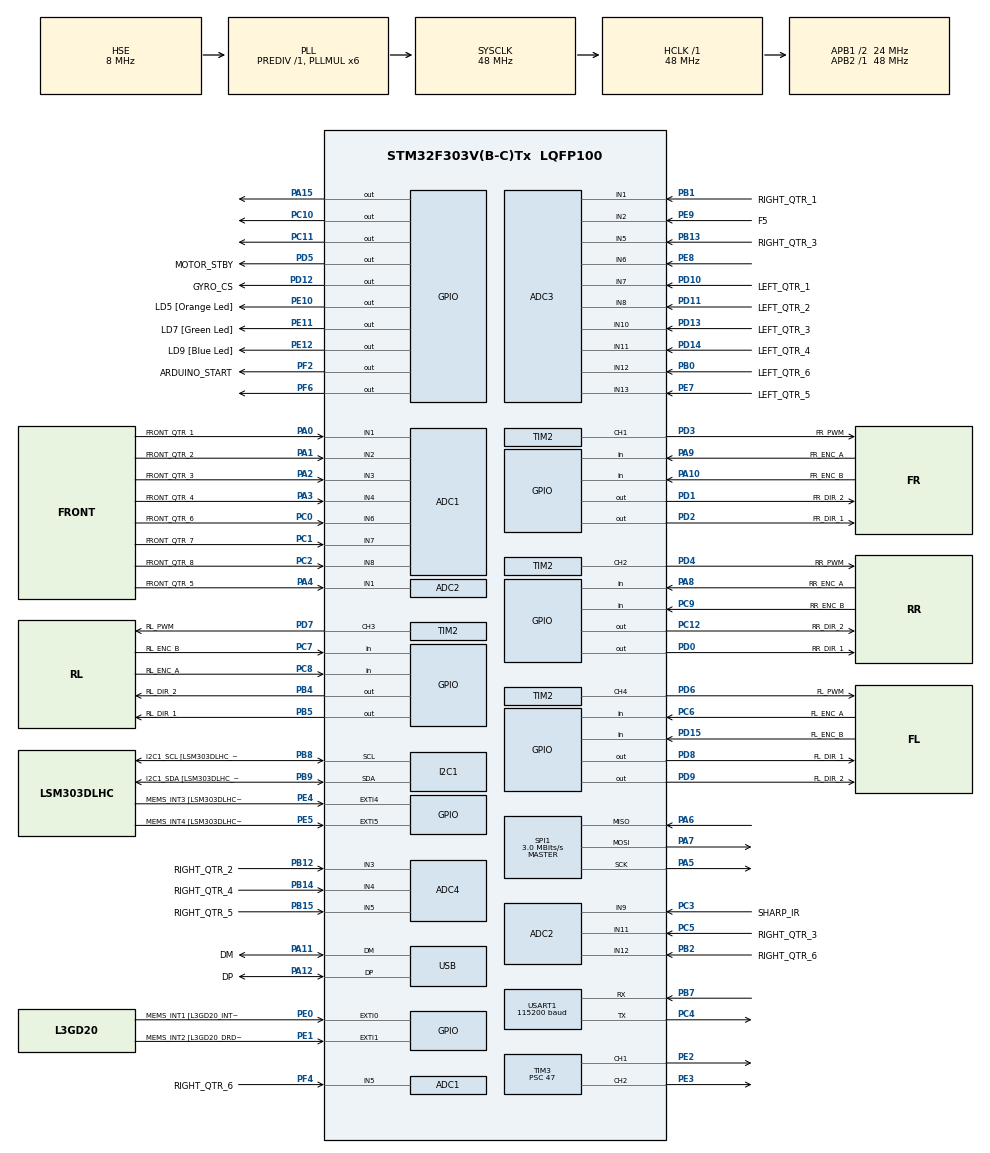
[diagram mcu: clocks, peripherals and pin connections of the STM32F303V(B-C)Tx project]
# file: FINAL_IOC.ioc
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ADC1.Channel-0\#ChannelRegularConversion=ADC_CHANNEL_6
ADC1.NbrOfConversionFlag=1
ADC1.Offset-0\#ChannelRegularConversion=0
ADC1.OffsetNumber-0\#ChannelRegularConversion=ADC_OFFSET_NONE
ADC1.Rank-0\#ChannelRegularConversion=1
ADC1.SamplingTime-0\#ChannelRegularConversion=ADC_SAMPLETIME_1CYCLE_5
ADC1.master=1
ADC2.Channel-0\#ChannelRegularConversion=ADC_CHANNEL_1
ADC2.NbrOfConversionFlag=1
ADC2.Offset-0\#ChannelRegularConversion=0
ADC2.OffsetNumber-0\#ChannelRegularConversion=ADC_OFFSET_NONE
ADC2.Rank-0\#ChannelRegularConversion=1
ADC2.SamplingTime-0\#ChannelRegularConversion=ADC_SAMPLETIME_1CYCLE_5
ADC3.Channel-0\#ChannelRegularConversion=ADC_CHANNEL_1
ADC3.NbrOfConversionFlag=1
ADC3.Offset-0\#ChannelRegularConversion=0
ADC3.OffsetNumber-0\#ChannelRegularConversion=ADC_OFFSET_NONE
ADC3.Rank-0\#ChannelRegularConversion=1
ADC3.SamplingTime-0\#ChannelRegularConversion=ADC_SAMPLETIME_1CYCLE_5
ADC3.master=1
ADC4.Channel-0\#ChannelRegularConversion=ADC_CHANNEL_3
ADC4.NbrOfConversionFlag=1
ADC4.Offset-0\#ChannelRegularConversion=0
ADC4.OffsetNumber-0\#ChannelRegularConversion=ADC_OFFSET_NONE
ADC4.Rank-0\#ChannelRegularConversion=1
ADC4.SamplingTime-0\#ChannelRegularConversion=ADC_SAMPLETIME_1CYCLE_5
Dma.ADC3.0.Direction=DMA_PERIPH_TO_MEMORY
Dma.ADC3.0.Instance=DMA2_Channel5
Dma.ADC3.0.MemDataAlignment=DMA_MDATAALIGN_HALFWORD
Dma.ADC3.0.MemInc=DMA_MINC_ENABLE
Dma.ADC3.0.Mode=DMA_CIRCULAR
Dma.ADC3.0.PeriphDataAlignment=DMA_PDATAALIGN_HALFWORD
Dma.ADC3.0.PeriphInc=DMA_PINC_DISABLE
Dma.ADC3.0.Priority=DMA_PRIORITY_LOW
Dma.Request0=ADC3
I2C1.Timing=0x00201D2B
Mcu.Family=STM32F3
Mcu.Name=STM32F303V(B-C)Tx
Mcu.Package=LQFP100
NVIC.ADC3_IRQn=true\:0\:0\:false\:false\:true\:true\:true\:true
NVIC.ADC4_IRQn=true\:0\:0\:false\:false\:true\:true\:true\:true
NVIC.DMA2_Channel5_IRQn=true\:0\:0\:false\:false\:true\:false\:true\:true
NVIC.PriorityGroup=NVIC_PRIORITYGROUP_0
NVIC.TIM6_DAC_IRQn=true\:0\:0\:false\:false\:true\:true\:true\:true
PA0.GPIO_Label=FRONT_QTR_1
PA0.Mode=IN1-Single-Ended
PA0.Signal=ADC1_IN1
PA1.GPIO_Label=FRONT_QTR_2
PA1.Mode=IN2-Single-Ended
PA1.Signal=ADC1_IN2
PA10.GPIO_Label=FR_ENC_B
PA10.GPIO_PuPd=GPIO_PULLUP
PA10.Signal=GPIO_Input
PA11.GPIO_Label=DM
PA11.Mode=Device
PA11.Signal=USB_DM
PA12.GPIO_Label=DP
PA12.Mode=Device
PA12.Signal=USB_DP
PA13.GPIO_Label=SWDIO
PA13.Mode=Serial_Wire
PA13.Signal=SYS_JTMS-SWDIO
PA14.Mode=Serial_Wire
PA14.Signal=SYS_JTCK-SWCLK
PA15.Signal=GPIO_Output
PA2.GPIO_Label=FRONT_QTR_3
PA2.Mode=IN3-Single-Ended
PA2.Signal=ADC1_IN3
PA3.GPIO_Label=FRONT_QTR_4
PA3.Mode=IN4-Single-Ended
PA3.Signal=ADC1_IN4
PA4.GPIO_Label=FRONT_QTR_5
PA4.Mode=IN1-Single-Ended
PA4.Signal=ADC2_IN1
PA5.Mode=Full_Duplex_Master
PA5.Signal=SPI1_SCK
PA6.Mode=Full_Duplex_Master
PA6.Signal=SPI1_MISO
PA7.Mode=Full_Duplex_Master
PA7.Signal=SPI1_MOSI
PA8.GPIO_Label=RR_ENC_A
PA8.GPIO_PuPd=GPIO_PULLUP
PA8.Signal=GPIO_Input
PA9.GPIO_Label=FR_ENC_A
PA9.GPIO_PuPd=GPIO_PULLUP
PA9.Signal=GPIO_Input
PB0.GPIO_Label=LEFT_QTR_6
PB0.Mode=IN12-Single-Ended
PB0.Signal=ADC3_IN12
PB1.GPIO_Label=RIGHT_QTR_1
PB1.Mode=IN1-Single-Ended
PB1.Signal=ADC3_IN1
PB12.GPIO_Label=RIGHT_QTR_2
PB12.Mode=IN3-Single-Ended
PB12.Signal=ADC4_IN3
PB13.GPIO_Label=RIGHT_QTR_3
PB13.Mode=IN5-Single-Ended
PB13.Signal=ADC3_IN5
PB14.GPIO_Label=RIGHT_QTR_4
PB14.Mode=IN4-Single-Ended
PB14.Signal=ADC4_IN4
PB15.GPIO_Label=RIGHT_QTR_5
PB15.Mode=IN5-Single-Ended
PB15.Signal=ADC4_IN5
PB2.GPIO_Label=RIGHT_QTR_6
PB2.Mode=IN12-Single-Ended
PB2.Signal=ADC2_IN12
PB3.GPIO_Label=SWO
PB3.Signal=SYS_JTDO-TRACESWO
PB4.GPIO_Label=RL_DIR_2
PB4.Signal=GPIO_Output
PB5.GPIO_Label=RL_DIR_1
PB5.Signal=GPIO_Output
PB7.Mode=Asynchronous
PB7.Signal=USART1_RX
PB8.GPIO_Label=I2C1_SCL [LSM303DLHC_SCL]
PB8.GPIO_Pu=GPIO_PULLUP
PB8.Mode=I2C
PB8.Signal=I2C1_SCL
PB9.GPIO_Label=I2C1_SDA [LSM303DLHC_SDA]
PB9.GPIO_Pu=GPIO_PULLUP
PB9.Mode=I2C
PB9.Signal=I2C1_SDA
PC0.GPIO_Label=FRONT_QTR_6
PC0.Signal=ADCx_IN6
PC1.GPIO_Label=FRONT_QTR_7
PC1.Signal=ADCx_IN7
PC10.Signal=GPIO_Output
PC11.Signal=GPIO_Output
PC12.GPIO_Label=RR_DIR_2
PC12.Signal=GPIO_Output
PC14-OSC32_IN.GPIO_Label=OSC32_IN
PC14-OSC32_IN.Signal=RCC_OSC32_IN
PC15-OSC32_OUT.GPIO_Label=OSC32_OUT
PC15-OSC32_OUT.Signal=RCC_OSC32_OUT
PC2.GPIO_Label=FRONT_QTR_8
PC2.Signal=ADCx_IN8
PC3.GPIO_Label=SHARP_IR
PC3.Signal=ADCx_IN9
PC4.Mode=Asynchronous
PC4.Signal=USART1_TX
PC5.GPIO_Label=RIGHT_QTR_3
PC5.Mode=IN11-Single-Ended
PC5.Signal=ADC2_IN11
PC6.GPIO_Label=FL_ENC_A
PC6.GPIO_PuPd=GPIO_PULLUP
PC6.Signal=GPIO_Input
PC7.GPIO_Label=RL_ENC_B
PC7.GPIO_PuPd=GPIO_PULLUP
PC7.Signal=GPIO_Input
PC8.GPIO_Label=RL_ENC_A
PC8.GPIO_PuPd=GPIO_PULLUP
PC8.Signal=GPIO_Input
PC9.GPIO_Label=RR_ENC_B
PC9.GPIO_PuPd=GPIO_PULLUP
PC9.Signal=GPIO_Input
PD0.GPIO_Label=RR_DIR_1
PD0.Signal=GPIO_Output
PD1.GPIO_Label=FR_DIR_2
PD1.Signal=GPIO_Output
PD10.GPIO_Label=LEFT_QTR_1
PD10.Signal=ADCx_IN7P
PD11.GPIO_Label=LEFT_QTR_2
PD11.Signal=ADCx_IN8P
PD12.GPIO_Label=GYRO_CS
PD12.PinState=GPIO_PIN_SET
PD12.Signal=GPIO_Output
PD13.GPIO_Label=LEFT_QTR_3
PD13.Signal=ADCx_IN10P
PD14.GPIO_Label=LEFT_QTR_4
PD14.Signal=ADCx_IN11
PD15.GPIO_Label=FL_ENC_B
PD15.GPIO_PuPd=GPIO_PULLUP
PD15.Signal=GPIO_Input
PD2.GPIO_Label=FR_DIR_1
PD2.Signal=GPIO_Output
PD3.GPIO_Label=FR_PWM
PD3.Signal=S_TIM2_CH1_ETR
PD4.GPIO_Label=RR_PWM
PD4.Signal=S_TIM2_CH2
PD5.GPIO_Label=MOTOR_STBY
PD5.Signal=GPIO_Output
PD6.GPIO_Label=FL_PWM
PD6.Signal=S_TIM2_CH4
PD7.GPIO_Label=RL_PWM
PD7.Signal=S_TIM2_CH3
PD8.GPIO_Label=FL_DIR_1
PD8.Signal=GPIO_Output
PD9.GPIO_Label=FL_DIR_2
PD9.Signal=GPIO_Output
PE0.GPIO_Label=MEMS_INT1 [L3GD20_INT1]
PE0.GPIO_ModeDefaultEXTI=GPIO_MODE_EVT_RISING
PE0.Signal=GPXTI0
PE1.GPIO_Label=MEMS_INT2 [L3GD20_DRDY/INT2]
PE1.GPIO_ModeDefaultEXTI=GPIO_MODE_EVT_RISING
PE1.Signal=GPXTI1
PE10.GPIO_Label=LD5 [Orange Led]
PE10.Signal=GPIO_Output
PE11.GPIO_Label=LD7 [Green Led]
PE11.Signal=GPIO_Output
PE12.GPIO_Label=LD9 [Blue Led]
PE12.Signal=GPIO_Output
PE2.Signal=S_TIM3_CH1
PE3.Signal=S_TIM3_CH2
PE4.GPIO_Label=MEMS_INT3 [LSM303DLHC_INT1]
PE4.GPIO_ModeDefaultEXTI=GPIO_MODE_EVT_RISING
PE4.Signal=GPXTI4
PE5.GPIO_Label=MEMS_INT4 [LSM303DLHC_INT2]
PE5.GPIO_ModeDefaultEXTI=GPIO_MODE_EVT_RISING
PE5.Signal=GPXTI5
PE7.GPIO_Label=LEFT_QTR_5
PE7.Mode=IN13-Single-Ended
PE7.Signal=ADC3_IN13
PE8.Signal=ADCx_IN6P
PE9.GPIO_Label=F5
PE9.Mode=IN2-Single-Ended
PE9.Signal=ADC3_IN2
PF0-OSC_IN.GPIO_Label=OSC_IN
PF0-OSC_IN.Mode=HSE-External-Clock-Source
PF0-OSC_IN.Signal=RCC_OSC_IN
PF1-OSC_OUT.GPIO_Label=OSC_OUT
PF1-OSC_OUT.Signal=RCC_OSC_OUT
PF2.GPIO_Label=ARDUINO_START
PF2.Signal=GPIO_Output
PF4.GPIO_Label=RIGHT_QTR_6
PF4.Mode=IN5-Single-Ended
PF4.Signal=ADC1_IN5
PF6.Signal=GPIO_Output
ProjectManager.HeapSize=0x200
ProjectManager.StackSize=0x400
ProjectManager.TargetToolchain=CMake
RCC.AHBFreq_Value=48000000
RCC.APB1CLKDivider=RCC_HCLK_DIV2
RCC.APB1Freq_Value=24000000
RCC.APB1TimFreq_Value=48000000
RCC.APB2Freq_Value=48000000
RCC.APB2TimFreq_Value=48000000
RCC.CortexFreq_Value=48000000
RCC.HCLKFreq_Value=48000000
RCC.HSE_VALUE=8000000
RCC.HSI_VALUE=8000000
RCC.LSE_VALUE=32768
RCC.PLLMUL=RCC_PLL_MUL6
RCC.SYSCLKFreq_VALUE=48000000
RCC.SYSCLKSourceVirtual=RCC_SYSCLKSOURCE_PLLCLK
RCC.USBFreq_Value=48000000
SH.ADCx_IN10P.0=ADC3_IN10,IN10-Single-Ended
SH.ADCx_IN11.0=ADC3_IN11,IN11-Single-Ended
SH.ADCx_IN6.0=ADC1_IN6,IN6-Single-Ended
SH.ADCx_IN6P.0=ADC3_IN6,IN6-Single-Ended
SH.ADCx_IN7.0=ADC1_IN7,IN7-Single-Ended
SH.ADCx_IN7P.0=ADC3_IN7,IN7-Single-Ended
SH.ADCx_IN8.0=ADC1_IN8,IN8-Single-Ended
SH.ADCx_IN8P.0=ADC3_IN8,IN8-Single-Ended
SH.ADCx_IN9.0=ADC2_IN9,IN9-Single-Ended
SH.S_TIM2_CH1_ETR.0=TIM2_CH1,PWM Generation1 CH1
SH.S_TIM2_CH2.0=TIM2_CH2,PWM Generation2 CH2
SH.S_TIM2_CH3.0=TIM2_CH3,PWM Generation3 CH3
SH.S_TIM2_CH4.0=TIM2_CH4,PWM Generation4 CH4
SH.S_TIM3_CH1.0=TIM3_CH1,PWM Generation1 CH1
SH.S_TIM3_CH2.0=TIM3_CH2,PWM Generation2 CH2
SPI1.BaudRatePrescaler=SPI_BAUDRATEPRESCALER_16
SPI1.CLKPhase=SPI_PHASE_2EDGE
SPI1.CLKPolarity=SPI_POLARITY_HIGH
SPI1.CalculateBaudRate=3.0 MBits/s
SPI1.DataSize=SPI_DATASIZE_8BIT
SPI1.Direction=SPI_DIRECTION_2LINES
SPI1.Mode=SPI_MODE_MASTER
SPI1.VirtualType=VM_MASTER
TIM2.Channel-PWM\ Generation1\ CH1=TIM_CHANNEL_1
TIM2.Channel-PWM\ Generation2\ CH2=TIM_CHANNEL_2
TIM2.Channel-PWM\ Generation3\ CH3=TIM_CHANNEL_3
TIM2.Channel-PWM\ Generation4\ CH4=TIM_CHANNEL_4
TIM2.Period=4799
TIM3.Channel-PWM\ Generation1\ CH1=TIM_CHANNEL_1
TIM3.Channel-PWM\ Generation2\ CH2=TIM_CHANNEL_2
TIM3.Period=19999
TIM3.Prescaler=47
TIM6.Period=2399 
USART1.BaudRate=115200
USART1.Mode=MODE_TX
USART1.VirtualMode-Asynchronous=VM_ASYNC
VP_TIM1_VS_ClockSourceINT.Mode=Internal
VP_TIM2_VS_ClockSourceINT.Mode=Internal
VP_TIM3_VS_ClockSourceINT.Mode=Internal
VP_TIM6_VS_ClockSourceINT.Mode=Enable_Timer
board=STM32F3DISCOVERY

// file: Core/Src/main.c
/* USER CODE BEGIN Header */
/**
  ******************************************************************************
  * @file           : main.c
  * @brief          : Main program body
  ******************************************************************************
  * @attention
  *
  * Copyright (c) 2026 STMicroelectronics.
  * All rights reserved.
  *
  * This software is licensed under terms that can be found in the LICENSE file
  * in the root directory of this software component.
  * If no LICENSE file comes with this software, it is provided AS-IS.
  *
  ******************************************************************************
  */
/* USER CODE END Header */
#include "main.h"

/* USER CODE BEGIN Includes */
#include "robot_core.h"
#include <stdio.h>
#include <stdbool.h>
#include "tcs34725.h"
/* USER CODE END Includes */

ADC_HandleTypeDef hadc1;
ADC_HandleTypeDef hadc2;
ADC_HandleTypeDef hadc3;
ADC_HandleTypeDef hadc4;
DMA_HandleTypeDef hdma_adc3;

I2C_HandleTypeDef hi2c1;

SPI_HandleTypeDef hspi1;

TIM_HandleTypeDef htim1;
TIM_HandleTypeDef htim2;
TIM_HandleTypeDef htim3;
TIM_HandleTypeDef htim6;

UART_HandleTypeDef huart1;

PCD_HandleTypeDef hpcd_USB_FS;

void SystemClock_Config(void);
static void MX_GPIO_Init(void);
static void MX_DMA_Init(void);
static void MX_TIM2_Init(void);
static void MX_USB_PCD_Init(void);
static void MX_TIM1_Init(void);
static void MX_TIM3_Init(void);
static void MX_USART1_UART_Init(void);
static void MX_TIM6_Init(void);
static void MX_ADC1_Init(void);
static void MX_ADC2_Init(void);
static void MX_ADC3_Init(void);
static void MX_ADC4_Init(void);
static void MX_SPI1_Init(void);
static void MX_I2C1_Init(void);

/* USER CODE BEGIN 0 */
int _write(int file, char *ptr, int len) {
    HAL_UART_Transmit(&huart1, (uint8_t*)ptr, len, HAL_MAX_DELAY);
    return len;
}

// // Trapezoidal Deceleration: Smoothly ramps down motor speeds to 0 to protect power supplies
// void Chassis_SmoothStop(Mecanum_Chassis_t *ch, int32_t start_vx, int32_t start_vy, int32_t start_omega, uint32_t duration_ms) {
//     uint32_t steps = 6;
//     uint32_t step_delay = duration_ms / steps;
//     for (int i = (int)steps; i >= 0; i--) {
//         int32_t vx = (start_vx * i) / (int32_t)steps;
//         int32_t vy = (start_vy * i) / (int32_t)steps;
//         int32_t omega = (start_omega * i) / (int32_t)steps;
//         Chassis_Drive(ch, vx, vy, omega);
//         HAL_Delay(step_delay);
//     }
//     Chassis_Drive(ch, 0, 0, 0);
// }
/* USER CODE END 0 */

int main(void)
{

  /* MCU Configuration--------------------------------------------------------*/

  /* Reset of all peripherals, Initializes the Flash interface and the Systick. */
  HAL_Init();

  /* Configure the system clock */
  SystemClock_Config();

  /* USER CODE BEGIN SysInit */
  MX_USART1_UART_Init();
  printf("\r\n==================================\r\n");
  printf("  NERC ROBOT EARLY BOOT DIAGNOSTIC\r\n");
  printf("==================================\r\n");
  /* USER CODE END SysInit */

  /* Initialize all configured peripherals */
  MX_GPIO_Init();
  MX_DMA_Init();
  MX_TIM2_Init();
  MX_USB_PCD_Init();
  MX_TIM1_Init();
  MX_TIM3_Init();
  MX_USART1_UART_Init();
  MX_TIM6_Init();
  MX_ADC1_Init();
  MX_ADC2_Init();
  MX_ADC3_Init();
  MX_ADC4_Init();
  MX_SPI1_Init();
  MX_I2C1_Init();
  /* USER CODE BEGIN 2 */
  HAL_ADCEx_Calibration_Start(&hadc1, ADC_SINGLE_ENDED);
  HAL_ADCEx_Calibration_Start(&hadc2, ADC_SINGLE_ENDED);
  HAL_ADCEx_Calibration_Start(&hadc3, ADC_SINGLE_ENDED);
  HAL_ADCEx_Calibration_Start(&hadc4, ADC_SINGLE_ENDED);

  if (TCS34725_Init(&hi2c1) != HAL_OK) {
      /* Initialization Error handling could go here */
      printf("TCS34725 Init Failed!\r\n");
  }

  Robot_Init();
  /* USER CODE END 2 */

  /* Infinite loop */
  while (1)
  {

    /* USER CODE BEGIN 3 */
    Robot_RunLoop();
  }
  /* USER CODE END 3 */
}

void SystemClock_Config(void)
{
  RCC_OscInitTypeDef RCC_OscInitStruct = {0};
  RCC_ClkInitTypeDef RCC_ClkInitStruct = {0};
  RCC_PeriphCLKInitTypeDef PeriphClkInit = {0};

  /** Initializes the RCC Oscillators according to the specified parameters
  * in the RCC_OscInitTypeDef structure.
  */
  RCC_OscInitStruct.OscillatorType = RCC_OSCILLATORTYPE_HSI|RCC_OSCILLATORTYPE_HSE;
  RCC_OscInitStruct.HSEState = RCC_HSE_BYPASS;
  RCC_OscInitStruct.HSEPredivValue = RCC_HSE_PREDIV_DIV1;
  RCC_OscInitStruct.HSIState = RCC_HSI_ON;
  RCC_OscInitStruct.HSICalibrationValue = RCC_HSICALIBRATION_DEFAULT;
  RCC_OscInitStruct.PLL.PLLState = RCC_PLL_ON;
  RCC_OscInitStruct.PLL.PLLSource = RCC_PLLSOURCE_HSE;
  RCC_OscInitStruct.PLL.PLLMUL = RCC_PLL_MUL6;
  if (HAL_RCC_OscConfig(&RCC_OscInitStruct) != HAL_OK)
  {
    Error_Handler();
  }

  /** Initializes the CPU, AHB and APB buses clocks
  */
  RCC_ClkInitStruct.ClockType = RCC_CLOCKTYPE_HCLK|RCC_CLOCKTYPE_SYSCLK
                              |RCC_CLOCKTYPE_PCLK1|RCC_CLOCKTYPE_PCLK2;
  RCC_ClkInitStruct.SYSCLKSource = RCC_SYSCLKSOURCE_PLLCLK;
  RCC_ClkInitStruct.AHBCLKDivider = RCC_SYSCLK_DIV1;
  RCC_ClkInitStruct.APB1CLKDivider = RCC_HCLK_DIV2;
  RCC_ClkInitStruct.APB2CLKDivider = RCC_HCLK_DIV1;

  if (HAL_RCC_ClockConfig(&RCC_ClkInitStruct, FLASH_LATENCY_1) != HAL_OK)
  {
    Error_Handler();
  }
  PeriphClkInit.PeriphClockSelection = RCC_PERIPHCLK_USB|RCC_PERIPHCLK_USART1
                              |RCC_PERIPHCLK_I2C1|RCC_PERIPHCLK_TIM1
                              |RCC_PERIPHCLK_ADC12|RCC_PERIPHCLK_ADC34;
  PeriphClkInit.Usart1ClockSelection = RCC_USART1CLKSOURCE_PCLK2;
  PeriphClkInit.Adc12ClockSelection = RCC_ADC12PLLCLK_DIV1;
  PeriphClkInit.Adc34ClockSelection = RCC_ADC34PLLCLK_DIV1;
  PeriphClkInit.I2c1ClockSelection = RCC_I2C1CLKSOURCE_HSI;
  PeriphClkInit.USBClockSelection = RCC_USBCLKSOURCE_PLL;
  PeriphClkInit.Tim1ClockSelection = RCC_TIM1CLK_HCLK;
  if (HAL_RCCEx_PeriphCLKConfig(&PeriphClkInit) != HAL_OK)
  {
    Error_Handler();
  }
}

static void MX_ADC1_Init(void)
{

  ADC_MultiModeTypeDef multimode = {0};
  ADC_ChannelConfTypeDef sConfig = {0};

  /** Common config
  */
  hadc1.Instance = ADC1;
  hadc1.Init.ClockPrescaler = ADC_CLOCK_ASYNC_DIV1;
  hadc1.Init.Resolution = ADC_RESOLUTION_12B;
  hadc1.Init.ScanConvMode = ADC_SCAN_DISABLE;
  hadc1.Init.ContinuousConvMode = DISABLE;
  hadc1.Init.DiscontinuousConvMode = DISABLE;
  hadc1.Init.ExternalTrigConvEdge = ADC_EXTERNALTRIGCONVEDGE_NONE;
  hadc1.Init.ExternalTrigConv = ADC_SOFTWARE_START;
  hadc1.Init.DataAlign = ADC_DATAALIGN_RIGHT;
  hadc1.Init.NbrOfConversion = 1;
  hadc1.Init.DMAContinuousRequests = DISABLE;
  hadc1.Init.EOCSelection = ADC_EOC_SINGLE_CONV;
  hadc1.Init.LowPowerAutoWait = DISABLE;
  hadc1.Init.Overrun = ADC_OVR_DATA_OVERWRITTEN;
  if (HAL_ADC_Init(&hadc1) != HAL_OK)
  {
    Error_Handler();
  }

  /** Configure the ADC multi-mode
  */
  multimode.Mode = ADC_MODE_INDEPENDENT;
  if (HAL_ADCEx_MultiModeConfigChannel(&hadc1, &multimode) != HAL_OK)
  {
    Error_Handler();
  }

  /** Configure Regular Channel
  */
  sConfig.Channel = ADC_CHANNEL_6;
  sConfig.Rank = ADC_REGULAR_RANK_1;
  sConfig.SingleDiff = ADC_SINGLE_ENDED;
  sConfig.SamplingTime = ADC_SAMPLETIME_1CYCLE_5;
  sConfig.OffsetNumber = ADC_OFFSET_NONE;
  sConfig.Offset = 0;
  if (HAL_ADC_ConfigChannel(&hadc1, &sConfig) != HAL_OK)
  {
    Error_Handler();
  }

}

static void MX_ADC2_Init(void)
{

  ADC_ChannelConfTypeDef sConfig = {0};

  /** Common config
  */
  hadc2.Instance = ADC2;
  hadc2.Init.ClockPrescaler = ADC_CLOCK_ASYNC_DIV1;
  hadc2.Init.Resolution = ADC_RESOLUTION_12B;
  hadc2.Init.ScanConvMode = ADC_SCAN_DISABLE;
  hadc2.Init.ContinuousConvMode = DISABLE;
  hadc2.Init.DiscontinuousConvMode = DISABLE;
  hadc2.Init.ExternalTrigConvEdge = ADC_EXTERNALTRIGCONVEDGE_NONE;
  hadc2.Init.ExternalTrigConv = ADC_SOFTWARE_START;
  hadc2.Init.DataAlign = ADC_DATAALIGN_RIGHT;
  hadc2.Init.NbrOfConversion = 1;
  hadc2.Init.DMAContinuousRequests = DISABLE;
  hadc2.Init.EOCSelection = ADC_EOC_SINGLE_CONV;
  hadc2.Init.LowPowerAutoWait = DISABLE;
  hadc2.Init.Overrun = ADC_OVR_DATA_OVERWRITTEN;
  if (HAL_ADC_Init(&hadc2) != HAL_OK)
  {
    Error_Handler();
  }

  /** Configure Regular Channel
  */
  sConfig.Channel = ADC_CHANNEL_1;
  sConfig.Rank = ADC_REGULAR_RANK_1;
  sConfig.SingleDiff = ADC_SINGLE_ENDED;
  sConfig.SamplingTime = ADC_SAMPLETIME_1CYCLE_5;
  sConfig.OffsetNumber = ADC_OFFSET_NONE;
  sConfig.Offset = 0;
  if (HAL_ADC_ConfigChannel(&hadc2, &sConfig) != HAL_OK)
  {
    Error_Handler();
  }

}

static void MX_ADC3_Init(void)
{

  ADC_MultiModeTypeDef multimode = {0};
  ADC_ChannelConfTypeDef sConfig = {0};

  /** Common config
  */
  hadc3.Instance = ADC3;
  hadc3.Init.ClockPrescaler = ADC_CLOCK_ASYNC_DIV1;
  hadc3.Init.Resolution = ADC_RESOLUTION_12B;
  hadc3.Init.ScanConvMode = ADC_SCAN_DISABLE;
  hadc3.Init.ContinuousConvMode = DISABLE;
  hadc3.Init.DiscontinuousConvMode = DISABLE;
  hadc3.Init.ExternalTrigConvEdge = ADC_EXTERNALTRIGCONVEDGE_NONE;
  hadc3.Init.ExternalTrigConv = ADC_SOFTWARE_START;
  hadc3.Init.DataAlign = ADC_DATAALIGN_RIGHT;
  hadc3.Init.NbrOfConversion = 1;
  hadc3.Init.DMAContinuousRequests = DISABLE;
  hadc3.Init.EOCSelection = ADC_EOC_SINGLE_CONV;
  hadc3.Init.LowPowerAutoWait = DISABLE;
  hadc3.Init.Overrun = ADC_OVR_DATA_OVERWRITTEN;
  if (HAL_ADC_Init(&hadc3) != HAL_OK)
  {
    Error_Handler();
  }

  /** Configure the ADC multi-mode
  */
  multimode.Mode = ADC_MODE_INDEPENDENT;
  if (HAL_ADCEx_MultiModeConfigChannel(&hadc3, &multimode) != HAL_OK)
  {
    Error_Handler();
  }

  /** Configure Regular Channel
  */
  sConfig.Channel = ADC_CHANNEL_1;
  sConfig.Rank = ADC_REGULAR_RANK_1;
  sConfig.SingleDiff = ADC_SINGLE_ENDED;
  sConfig.SamplingTime = ADC_SAMPLETIME_1CYCLE_5;
  sConfig.OffsetNumber = ADC_OFFSET_NONE;
  sConfig.Offset = 0;
  if (HAL_ADC_ConfigChannel(&hadc3, &sConfig) != HAL_OK)
  {
    Error_Handler();
  }

}

static void MX_ADC4_Init(void)
{

  ADC_ChannelConfTypeDef sConfig = {0};

  /** Common config
  */
  hadc4.Instance = ADC4;
  hadc4.Init.ClockPrescaler = ADC_CLOCK_ASYNC_DIV1;
  hadc4.Init.Resolution = ADC_RESOLUTION_12B;
  hadc4.Init.ScanConvMode = ADC_SCAN_DISABLE;
  hadc4.Init.ContinuousConvMode = DISABLE;
  hadc4.Init.DiscontinuousConvMode = DISABLE;
  hadc4.Init.ExternalTrigConvEdge = ADC_EXTERNALTRIGCONVEDGE_NONE;
  hadc4.Init.ExternalTrigConv = ADC_SOFTWARE_START;
  hadc4.Init.DataAlign = ADC_DATAALIGN_RIGHT;
  hadc4.Init.NbrOfConversion = 1;
  hadc4.Init.DMAContinuousRequests = DISABLE;
  hadc4.Init.EOCSelection = ADC_EOC_SINGLE_CONV;
  hadc4.Init.LowPowerAutoWait = DISABLE;
  hadc4.Init.Overrun = ADC_OVR_DATA_OVERWRITTEN;
  if (HAL_ADC_Init(&hadc4) != HAL_OK)
  {
    Error_Handler();
  }

  /** Configure Regular Channel
  */
  sConfig.Channel = ADC_CHANNEL_3;
  sConfig.Rank = ADC_REGULAR_RANK_1;
  sConfig.SingleDiff = ADC_SINGLE_ENDED;
  sConfig.SamplingTime = ADC_SAMPLETIME_1CYCLE_5;
  sConfig.OffsetNumber = ADC_OFFSET_NONE;
  sConfig.Offset = 0;
  if (HAL_ADC_ConfigChannel(&hadc4, &sConfig) != HAL_OK)
  {
    Error_Handler();
  }

}

static void MX_I2C1_Init(void)
{

  hi2c1.Instance = I2C1;
  hi2c1.Init.Timing = 0x00201D2B;
  hi2c1.Init.OwnAddress1 = 0;
  hi2c1.Init.AddressingMode = I2C_ADDRESSINGMODE_7BIT;
  hi2c1.Init.DualAddressMode = I2C_DUALADDRESS_DISABLE;
  hi2c1.Init.OwnAddress2 = 0;
  hi2c1.Init.OwnAddress2Masks = I2C_OA2_NOMASK;
  hi2c1.Init.GeneralCallMode = I2C_GENERALCALL_DISABLE;
  hi2c1.Init.NoStretchMode = I2C_NOSTRETCH_DISABLE;
  if (HAL_I2C_Init(&hi2c1) != HAL_OK)
  {
    Error_Handler();
  }

  /** Configure Analogue filter
  */
  if (HAL_I2CEx_ConfigAnalogFilter(&hi2c1, I2C_ANALOGFILTER_ENABLE) != HAL_OK)
  {
    Error_Handler();
  }

  /** Configure Digital filter
  */
  if (HAL_I2CEx_ConfigDigitalFilter(&hi2c1, 0) != HAL_OK)
  {
    Error_Handler();
  }

}

static void MX_SPI1_Init(void)
{

  /* SPI1 parameter configuration*/
  hspi1.Instance = SPI1;
  hspi1.Init.Mode = SPI_MODE_MASTER;
  hspi1.Init.Direction = SPI_DIRECTION_2LINES;
  hspi1.Init.DataSize = SPI_DATASIZE_8BIT;
  hspi1.Init.CLKPolarity = SPI_POLARITY_HIGH;
  hspi1.Init.CLKPhase = SPI_PHASE_2EDGE;
  hspi1.Init.NSS = SPI_NSS_SOFT;
  hspi1.Init.BaudRatePrescaler = SPI_BAUDRATEPRESCALER_16;
  hspi1.Init.FirstBit = SPI_FIRSTBIT_MSB;
  hspi1.Init.TIMode = SPI_TIMODE_DISABLE;
  hspi1.Init.CRCCalculation = SPI_CRCCALCULATION_DISABLE;
  hspi1.Init.CRCPolynomial = 7;
  hspi1.Init.CRCLength = SPI_CRC_LENGTH_DATASIZE;
  hspi1.Init.NSSPMode = SPI_NSS_PULSE_DISABLE;
  if (HAL_SPI_Init(&hspi1) != HAL_OK)
  {
    Error_Handler();
  }

}

static void MX_TIM1_Init(void)
{

  TIM_ClockConfigTypeDef sClockSourceConfig = {0};
  TIM_MasterConfigTypeDef sMasterConfig = {0};

  htim1.Instance = TIM1;
  htim1.Init.Prescaler = 0;
  htim1.Init.CounterMode = TIM_COUNTERMODE_UP;
  htim1.Init.Period = 65535;
  htim1.Init.ClockDivision = TIM_CLOCKDIVISION_DIV1;
  htim1.Init.RepetitionCounter = 0;
  htim1.Init.AutoReloadPreload = TIM_AUTORELOAD_PRELOAD_DISABLE;
  if (HAL_TIM_Base_Init(&htim1) != HAL_OK)
  {
    Error_Handler();
  }
  sClockSourceConfig.ClockSource = TIM_CLOCKSOURCE_INTERNAL;
  if (HAL_TIM_ConfigClockSource(&htim1, &sClockSourceConfig) != HAL_OK)
  {
    Error_Handler();
  }
  sMasterConfig.MasterOutputTrigger = TIM_TRGO_RESET;
  sMasterConfig.MasterOutputTrigger2 = TIM_TRGO2_RESET;
  sMasterConfig.MasterSlaveMode = TIM_MASTERSLAVEMODE_DISABLE;
  if (HAL_TIMEx_MasterConfigSynchronization(&htim1, &sMasterConfig) != HAL_OK)
  {
    Error_Handler();
  }

}

static void MX_TIM2_Init(void)
{

  TIM_ClockConfigTypeDef sClockSourceConfig = {0};
  TIM_MasterConfigTypeDef sMasterConfig = {0};
  TIM_OC_InitTypeDef sConfigOC = {0};

  htim2.Instance = TIM2;
  htim2.Init.Prescaler = 0;
  htim2.Init.CounterMode = TIM_COUNTERMODE_UP;
  htim2.Init.Period = 4799;
  htim2.Init.ClockDivision = TIM_CLOCKDIVISION_DIV1;
  htim2.Init.AutoReloadPreload = TIM_AUTORELOAD_PRELOAD_DISABLE;
  if (HAL_TIM_Base_Init(&htim2) != HAL_OK)
  {
    Error_Handler();
  }
  sClockSourceConfig.ClockSource = TIM_CLOCKSOURCE_INTERNAL;
  if (HAL_TIM_ConfigClockSource(&htim2, &sClockSourceConfig) != HAL_OK)
  {
    Error_Handler();
  }
  if (HAL_TIM_PWM_Init(&htim2) != HAL_OK)
  {
    Error_Handler();
  }
  sMasterConfig.MasterOutputTrigger = TIM_TRGO_RESET;
  sMasterConfig.MasterSlaveMode = TIM_MASTERSLAVEMODE_DISABLE;
  if (HAL_TIMEx_MasterConfigSynchronization(&htim2, &sMasterConfig) != HAL_OK)
  {
    Error_Handler();
  }
  sConfigOC.OCMode = TIM_OCMODE_PWM1;
  sConfigOC.Pulse = 0;
  sConfigOC.OCPolarity = TIM_OCPOLARITY_HIGH;
  sConfigOC.OCFastMode = TIM_OCFAST_DISABLE;
  if (HAL_TIM_PWM_ConfigChannel(&htim2, &sConfigOC, TIM_CHANNEL_1) != HAL_OK)
  {
    Error_Handler();
  }
  if (HAL_TIM_PWM_ConfigChannel(&htim2, &sConfigOC, TIM_CHANNEL_2) != HAL_OK)
  {
    Error_Handler();
  }
  if (HAL_TIM_PWM_ConfigChannel(&htim2, &sConfigOC, TIM_CHANNEL_3) != HAL_OK)
  {
    Error_Handler();
  }
  if (HAL_TIM_PWM_ConfigChannel(&htim2, &sConfigOC, TIM_CHANNEL_4) != HAL_OK)
  {
    Error_Handler();
  }
  HAL_TIM_MspPostInit(&htim2);

}

static void MX_TIM3_Init(void)
{

  TIM_ClockConfigTypeDef sClockSourceConfig = {0};
  TIM_MasterConfigTypeDef sMasterConfig = {0};
  TIM_OC_InitTypeDef sConfigOC = {0};

  htim3.Instance = TIM3;
  htim3.Init.Prescaler = 47;
  htim3.Init.CounterMode = TIM_COUNTERMODE_UP;
  htim3.Init.Period = 19999;
  htim3.Init.ClockDivision = TIM_CLOCKDIVISION_DIV1;
  htim3.Init.AutoReloadPreload = TIM_AUTORELOAD_PRELOAD_DISABLE;
  if (HAL_TIM_Base_Init(&htim3) != HAL_OK)
  {
    Error_Handler();
  }
  sClockSourceConfig.ClockSource = TIM_CLOCKSOURCE_INTERNAL;
  if (HAL_TIM_ConfigClockSource(&htim3, &sClockSourceConfig) != HAL_OK)
  {
    Error_Handler();
  }
  if (HAL_TIM_PWM_Init(&htim3) != HAL_OK)
  {
    Error_Handler();
  }
  sMasterConfig.MasterOutputTrigger = TIM_TRGO_RESET;
  sMasterConfig.MasterSlaveMode = TIM_MASTERSLAVEMODE_DISABLE;
  if (HAL_TIMEx_MasterConfigSynchronization(&htim3, &sMasterConfig) != HAL_OK)
  {
    Error_Handler();
  }
  sConfigOC.OCMode = TIM_OCMODE_PWM1;
  sConfigOC.Pulse = 0;
  sConfigOC.OCPolarity = TIM_OCPOLARITY_HIGH;
  sConfigOC.OCFastMode = TIM_OCFAST_DISABLE;
  if (HAL_TIM_PWM_ConfigChannel(&htim3, &sConfigOC, TIM_CHANNEL_1) != HAL_OK)
  {
    Error_Handler();
  }
  if (HAL_TIM_PWM_ConfigChannel(&htim3, &sConfigOC, TIM_CHANNEL_2) != HAL_OK)
  {
    Error_Handler();
  }
  HAL_TIM_MspPostInit(&htim3);

}

static void MX_TIM6_Init(void)
{

  TIM_MasterConfigTypeDef sMasterConfig = {0};

  htim6.Instance = TIM6;
  htim6.Init.Prescaler = 0;
  htim6.Init.CounterMode = TIM_COUNTERMODE_UP;
  htim6.Init.Period = 2399 ;
  htim6.Init.AutoReloadPreload = TIM_AUTORELOAD_PRELOAD_DISABLE;
  if (HAL_TIM_Base_Init(&htim6) != HAL_OK)
  {
    Error_Handler();
  }
  sMasterConfig.MasterOutputTrigger = TIM_TRGO_RESET;
  sMasterConfig.MasterSlaveMode = TIM_MASTERSLAVEMODE_DISABLE;
  if (HAL_TIMEx_MasterConfigSynchronization(&htim6, &sMasterConfig) != HAL_OK)
  {
    Error_Handler();
  }

}

static void MX_USART1_UART_Init(void)
{

  huart1.Instance = USART1;
  huart1.Init.BaudRate = 115200;
  huart1.Init.WordLength = UART_WORDLENGTH_8B;
  huart1.Init.StopBits = UART_STOPBITS_1;
  huart1.Init.Parity = UART_PARITY_NONE;
  huart1.Init.Mode = UART_MODE_TX;
  huart1.Init.HwFlowCtl = UART_HWCONTROL_NONE;
  huart1.Init.OverSampling = UART_OVERSAMPLING_16;
  huart1.Init.OneBitSampling = UART_ONE_BIT_SAMPLE_DISABLE;
  huart1.AdvancedInit.AdvFeatureInit = UART_ADVFEATURE_NO_INIT;
  if (HAL_UART_Init(&huart1) != HAL_OK)
  {
    Error_Handler();
  }

}

static void MX_USB_PCD_Init(void)
{

  hpcd_USB_FS.Instance = USB;
  hpcd_USB_FS.Init.dev_endpoints = 8;
  hpcd_USB_FS.Init.speed = PCD_SPEED_FULL;
  hpcd_USB_FS.Init.phy_itface = PCD_PHY_EMBEDDED;
  hpcd_USB_FS.Init.low_power_enable = DISABLE;
  hpcd_USB_FS.Init.battery_charging_enable = DISABLE;
  if (HAL_PCD_Init(&hpcd_USB_FS) != HAL_OK)
  {
    Error_Handler();
  }

}

static void MX_DMA_Init(void)
{

  /* DMA controller clock enable */
  __HAL_RCC_DMA2_CLK_ENABLE();

  /* DMA interrupt init */
  /* DMA2_Channel5_IRQn interrupt configuration */
  HAL_NVIC_SetPriority(DMA2_Channel5_IRQn, 0, 0);
  HAL_NVIC_EnableIRQ(DMA2_Channel5_IRQn);

}

static void MX_GPIO_Init(void)
{
  GPIO_InitTypeDef GPIO_InitStruct = {0};

  /* GPIO Ports Clock Enable */
  __HAL_RCC_GPIOE_CLK_ENABLE();
  __HAL_RCC_GPIOC_CLK_ENABLE();
  __HAL_RCC_GPIOF_CLK_ENABLE();
  __HAL_RCC_GPIOA_CLK_ENABLE();
  __HAL_RCC_GPIOB_CLK_ENABLE();
  __HAL_RCC_GPIOD_CLK_ENABLE();

  /*Configure GPIO pin Output Level */
  HAL_GPIO_WritePin(GPIOF, ARDUINO_START_Pin|GPIO_PIN_6, GPIO_PIN_RESET);

  /*Configure GPIO pin Output Level */
  HAL_GPIO_WritePin(GPIOE, LD5_Pin|LD7_Pin|LD9_Pin, GPIO_PIN_RESET);

  /*Configure GPIO pin Output Level */
  HAL_GPIO_WritePin(GPIOD, FL_DIR_1_Pin|FL_DIR_2_Pin|RR_DIR_1_Pin|FR_DIR_2_Pin
                          |FR_DIR_1_Pin|MOTOR_STBY_Pin, GPIO_PIN_RESET);

  /*Configure GPIO pin Output Level */
  HAL_GPIO_WritePin(GYRO_CS_GPIO_Port, GYRO_CS_Pin, GPIO_PIN_SET);

  /*Configure GPIO pin Output Level */
  HAL_GPIO_WritePin(GPIOA, GPIO_PIN_15, GPIO_PIN_RESET);

  /*Configure GPIO pin Output Level */
  HAL_GPIO_WritePin(GPIOC, GPIO_PIN_10|GPIO_PIN_11|RR_DIR_2_Pin, GPIO_PIN_RESET);

  /*Configure GPIO pin Output Level */
  HAL_GPIO_WritePin(GPIOB, RL_DIR_2_Pin|RL_DIR_1_Pin, GPIO_PIN_RESET);

  /*Configure GPIO pins : MEMS_INT3_Pin MEMS_INT4_Pin MEMS_INT1_Pin MEMS_INT2_Pin */
  GPIO_InitStruct.Pin = MEMS_INT3_Pin|MEMS_INT4_Pin|MEMS_INT1_Pin|MEMS_INT2_Pin;
  GPIO_InitStruct.Mode = GPIO_MODE_EVT_RISING;
  GPIO_InitStruct.Pull = GPIO_NOPULL;
  HAL_GPIO_Init(GPIOE, &GPIO_InitStruct);

  /*Configure GPIO pins : ARDUINO_START_Pin PF6 */
  GPIO_InitStruct.Pin = ARDUINO_START_Pin|GPIO_PIN_6;
  GPIO_InitStruct.Mode = GPIO_MODE_OUTPUT_PP;
  GPIO_InitStruct.Pull = GPIO_NOPULL;
  GPIO_InitStruct.Speed = GPIO_SPEED_FREQ_LOW;
  HAL_GPIO_Init(GPIOF, &GPIO_InitStruct);

  /*Configure GPIO pins : LD5_Pin LD7_Pin LD9_Pin */
  GPIO_InitStruct.Pin = LD5_Pin|LD7_Pin|LD9_Pin;
  GPIO_InitStruct.Mode = GPIO_MODE_OUTPUT_PP;
  GPIO_InitStruct.Pull = GPIO_NOPULL;
  GPIO_InitStruct.Speed = GPIO_SPEED_FREQ_LOW;
  HAL_GPIO_Init(GPIOE, &GPIO_InitStruct);

  /*Configure GPIO pins : FL_DIR_1_Pin FL_DIR_2_Pin GYRO_CS_Pin RR_DIR_1_Pin
                           FR_DIR_2_Pin FR_DIR_1_Pin MOTOR_STBY_Pin */
  GPIO_InitStruct.Pin = FL_DIR_1_Pin|FL_DIR_2_Pin|GYRO_CS_Pin|RR_DIR_1_Pin
                          |FR_DIR_2_Pin|FR_DIR_1_Pin|MOTOR_STBY_Pin;
  GPIO_InitStruct.Mode = GPIO_MODE_OUTPUT_PP;
  GPIO_InitStruct.Pull = GPIO_NOPULL;
  GPIO_InitStruct.Speed = GPIO_SPEED_FREQ_LOW;
  HAL_GPIO_Init(GPIOD, &GPIO_InitStruct);

  /*Configure GPIO pin : FL_ENC_B_Pin */
  GPIO_InitStruct.Pin = FL_ENC_B_Pin;
  GPIO_InitStruct.Mode = GPIO_MODE_INPUT;
  GPIO_InitStruct.Pull = GPIO_PULLUP;
  HAL_GPIO_Init(FL_ENC_B_GPIO_Port, &GPIO_InitStruct);

  /*Configure GPIO pins : FL_ENC_A_Pin RL_ENC_B_Pin RL_ENC_A_Pin RR_ENC_B_Pin */
  GPIO_InitStruct.Pin = FL_ENC_A_Pin|RL_ENC_B_Pin|RL_ENC_A_Pin|RR_ENC_B_Pin;
  GPIO_InitStruct.Mode = GPIO_MODE_INPUT;
  GPIO_InitStruct.Pull = GPIO_PULLUP;
  HAL_GPIO_Init(GPIOC, &GPIO_InitStruct);

  /*Configure GPIO pins : RR_ENC_A_Pin FR_ENC_A_Pin FR_ENC_B_Pin */
  GPIO_InitStruct.Pin = RR_ENC_A_Pin|FR_ENC_A_Pin|FR_ENC_B_Pin;
  GPIO_InitStruct.Mode = GPIO_MODE_INPUT;
  GPIO_InitStruct.Pull = GPIO_PULLUP;
  HAL_GPIO_Init(GPIOA, &GPIO_InitStruct);

  /*Configure GPIO pin : PA15 */
  GPIO_InitStruct.Pin = GPIO_PIN_15;
  GPIO_InitStruct.Mode = GPIO_MODE_OUTPUT_PP;
  GPIO_InitStruct.Pull = GPIO_NOPULL;
  GPIO_InitStruct.Speed = GPIO_SPEED_FREQ_LOW;
  HAL_GPIO_Init(GPIOA, &GPIO_InitStruct);

  /*Configure GPIO pins : PC10 PC11 RR_DIR_2_Pin */
  GPIO_InitStruct.Pin = GPIO_PIN_10|GPIO_PIN_11|RR_DIR_2_Pin;
  GPIO_InitStruct.Mode = GPIO_MODE_OUTPUT_PP;
  GPIO_InitStruct.Pull = GPIO_NOPULL;
  GPIO_InitStruct.Speed = GPIO_SPEED_FREQ_LOW;
  HAL_GPIO_Init(GPIOC, &GPIO_InitStruct);

  /*Configure GPIO pins : RL_DIR_2_Pin RL_DIR_1_Pin */
  GPIO_InitStruct.Pin = RL_DIR_2_Pin|RL_DIR_1_Pin;
  GPIO_InitStruct.Mode = GPIO_MODE_OUTPUT_PP;
  GPIO_InitStruct.Pull = GPIO_NOPULL;
  GPIO_InitStruct.Speed = GPIO_SPEED_FREQ_LOW;
  HAL_GPIO_Init(GPIOB, &GPIO_InitStruct);

}

void Error_Handler(void)
{
  __disable_irq();
  while (1)
  {
  }
}
